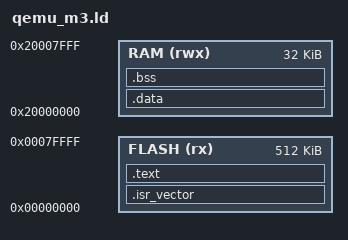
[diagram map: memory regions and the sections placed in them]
/* QEMU Cortex-M3 最小链接脚本 */

MEMORY
{
    FLASH (rx) : ORIGIN = 0x00000000, LENGTH = 512K
    RAM (rwx)  : ORIGIN = 0x20000000, LENGTH = 32K
}

SECTIONS
{
    .isr_vector : {
        . = ALIGN(4);
        KEEP(*(.isr_vector))
        . = ALIGN(4);
    } >FLASH

    .text : {
        . = ALIGN(4);
        *(.text)
        *(.text*)
        *(.rodata)
        *(.rodata*)
        . = ALIGN(4);
        _etext = .;
    } >FLASH

    .data : {
        . = ALIGN(4);
        _sdata = .;
        *(.data)
        *(.data*)
        . = ALIGN(4);
        _edata = .;
    } >RAM

    .bss : {
        . = ALIGN(4);
        _sbss = .;
        *(.bss)
        *(.bss*)
        *(COMMON)
        . = ALIGN(4);
        _ebss = .;
    } >RAM

    _stack_top = ORIGIN(RAM) + LENGTH(RAM);
}
